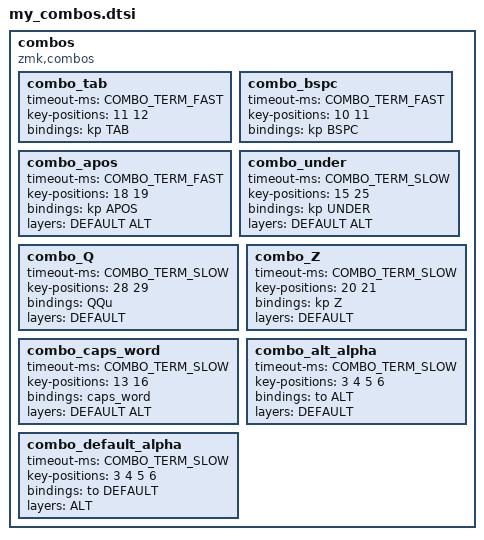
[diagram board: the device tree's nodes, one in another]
/*
        Key Positions for A.dux

0   1   2   3   4       5   6   7   8   9
10  11  12  13  14      15  16  17  18  19
20  21  22  23  24      25  26  27  28  29
            30  31      32  33

*/

#undef COMBO_HOOK
#define COMBO_HOOK global-quick-tap-ms = <125>;

#define COMBO_TERM_FAST 30
#define COMBO_TERM_SLOW 45


combos {
    compatible = "zmk,combos";

    combo_tab {
        timeout-ms = <COMBO_TERM_FAST>;
        key-positions = <11 12>;
        bindings = <&kp TAB>;
    };
    
    combo_bspc {
        timeout-ms = <COMBO_TERM_FAST>;
        key-positions = <10 11>;
        bindings = <&kp BSPC>;
    };
    
    combo_apos {
        timeout-ms = <COMBO_TERM_FAST>;
        key-positions = <18 19>;
        bindings = <&kp APOS>;
        layers = <DEFAULT ALT>;
    };

    combo_under {
        timeout-ms = <COMBO_TERM_SLOW>;
        key-positions = <15 25>;
        bindings = <&kp UNDER>;
        layers = <DEFAULT ALT>;
    };

    combo_Q {
        timeout-ms = <COMBO_TERM_SLOW>;
        key-positions = <28 29>;
        bindings = <&QQu>;
        layers = <DEFAULT>;
    };

    combo_Z {
        timeout-ms = <COMBO_TERM_SLOW>;
        key-positions = <20 21>;
        bindings = <&kp Z>;
        layers = <DEFAULT>;
    };
    
    combo_caps_word {
        timeout-ms = <COMBO_TERM_SLOW>;
        key-positions = <13 16>;
        bindings = <&caps_word>;
        layers = <DEFAULT ALT>;
    };

    combo_alt_alpha {
        timeout-ms = <COMBO_TERM_SLOW>;
        key-positions = <3 4 5 6>;
        bindings = <&to ALT>;
        layers = <DEFAULT>;
    };

    combo_default_alpha {
        timeout-ms = <COMBO_TERM_SLOW>;
        key-positions = <3 4 5 6>;
        bindings = <&to DEFAULT>;
        layers = <ALT>;
    };
};
